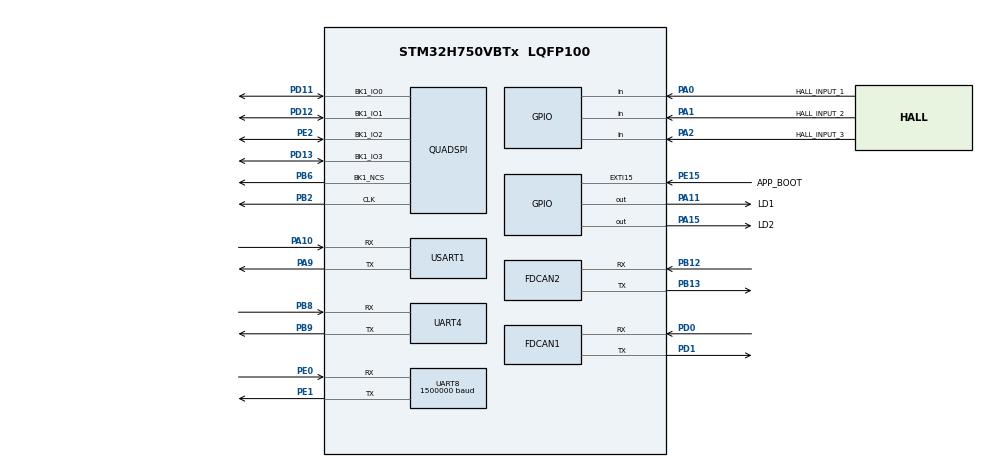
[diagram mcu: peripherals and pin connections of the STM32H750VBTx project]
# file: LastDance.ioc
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CORTEX_M7.CPU_ICache=Enabled
CORTEX_M7.default_mode_Activation=0
Dma.Request0=UART4_RX
Dma.Request1=UART8_TX
Dma.Request2=UART8_RX
Dma.Request3=USART1_TX
Dma.UART4_RX.0.Direction=DMA_PERIPH_TO_MEMORY
Dma.UART4_RX.0.EventEnable=DISABLE
Dma.UART4_RX.0.FIFOMode=DMA_FIFOMODE_DISABLE
Dma.UART4_RX.0.Instance=DMA1_Stream0
Dma.UART4_RX.0.MemDataAlignment=DMA_MDATAALIGN_BYTE
Dma.UART4_RX.0.MemInc=DMA_MINC_ENABLE
Dma.UART4_RX.0.Mode=DMA_NORMAL
Dma.UART4_RX.0.PeriphDataAlignment=DMA_PDATAALIGN_BYTE
Dma.UART4_RX.0.PeriphInc=DMA_PINC_DISABLE
Dma.UART4_RX.0.Polarity=HAL_DMAMUX_REQ_GEN_RISING
Dma.UART4_RX.0.Priority=DMA_PRIORITY_LOW
Dma.UART4_RX.0.RequestNumber=1
Dma.UART4_RX.0.SignalID=NONE
Dma.UART4_RX.0.SyncEnable=DISABLE
Dma.UART4_RX.0.SyncPolarity=HAL_DMAMUX_SYNC_NO_EVENT
Dma.UART4_RX.0.SyncRequestNumber=1
Dma.UART4_RX.0.SyncSignalID=NONE
Dma.UART8_RX.2.Direction=DMA_PERIPH_TO_MEMORY
Dma.UART8_RX.2.EventEnable=DISABLE
Dma.UART8_RX.2.FIFOMode=DMA_FIFOMODE_DISABLE
Dma.UART8_RX.2.Instance=DMA1_Stream2
Dma.UART8_RX.2.MemDataAlignment=DMA_MDATAALIGN_BYTE
Dma.UART8_RX.2.MemInc=DMA_MINC_ENABLE
Dma.UART8_RX.2.Mode=DMA_NORMAL
Dma.UART8_RX.2.PeriphDataAlignment=DMA_PDATAALIGN_BYTE
Dma.UART8_RX.2.PeriphInc=DMA_PINC_DISABLE
Dma.UART8_RX.2.Polarity=HAL_DMAMUX_REQ_GEN_RISING
Dma.UART8_RX.2.Priority=DMA_PRIORITY_LOW
Dma.UART8_RX.2.RequestNumber=1
Dma.UART8_RX.2.SignalID=NONE
Dma.UART8_RX.2.SyncEnable=DISABLE
Dma.UART8_RX.2.SyncPolarity=HAL_DMAMUX_SYNC_NO_EVENT
Dma.UART8_RX.2.SyncRequestNumber=1
Dma.UART8_RX.2.SyncSignalID=NONE
Dma.UART8_TX.1.Direction=DMA_MEMORY_TO_PERIPH
Dma.UART8_TX.1.EventEnable=DISABLE
Dma.UART8_TX.1.FIFOMode=DMA_FIFOMODE_DISABLE
Dma.UART8_TX.1.Instance=DMA1_Stream1
Dma.UART8_TX.1.MemDataAlignment=DMA_MDATAALIGN_BYTE
Dma.UART8_TX.1.MemInc=DMA_MINC_ENABLE
Dma.UART8_TX.1.Mode=DMA_NORMAL
Dma.UART8_TX.1.PeriphDataAlignment=DMA_PDATAALIGN_BYTE
Dma.UART8_TX.1.PeriphInc=DMA_PINC_DISABLE
Dma.UART8_TX.1.Polarity=HAL_DMAMUX_REQ_GEN_RISING
Dma.UART8_TX.1.Priority=DMA_PRIORITY_LOW
Dma.UART8_TX.1.RequestNumber=1
Dma.UART8_TX.1.SignalID=NONE
Dma.UART8_TX.1.SyncEnable=DISABLE
Dma.UART8_TX.1.SyncPolarity=HAL_DMAMUX_SYNC_NO_EVENT
Dma.UART8_TX.1.SyncRequestNumber=1
Dma.UART8_TX.1.SyncSignalID=NONE
Dma.USART1_TX.3.Direction=DMA_MEMORY_TO_PERIPH
Dma.USART1_TX.3.EventEnable=DISABLE
Dma.USART1_TX.3.FIFOMode=DMA_FIFOMODE_DISABLE
Dma.USART1_TX.3.Instance=DMA1_Stream3
Dma.USART1_TX.3.MemDataAlignment=DMA_MDATAALIGN_BYTE
Dma.USART1_TX.3.MemInc=DMA_MINC_ENABLE
Dma.USART1_TX.3.Mode=DMA_NORMAL
Dma.USART1_TX.3.PeriphDataAlignment=DMA_PDATAALIGN_BYTE
Dma.USART1_TX.3.PeriphInc=DMA_PINC_DISABLE
Dma.USART1_TX.3.Polarity=HAL_DMAMUX_REQ_GEN_RISING
Dma.USART1_TX.3.Priority=DMA_PRIORITY_LOW
Dma.USART1_TX.3.RequestNumber=1
Dma.USART1_TX.3.SignalID=NONE
Dma.USART1_TX.3.SyncEnable=DISABLE
Dma.USART1_TX.3.SyncPolarity=HAL_DMAMUX_SYNC_NO_EVENT
Dma.USART1_TX.3.SyncRequestNumber=1
Dma.USART1_TX.3.SyncSignalID=NONE
FDCAN1.AutoRetransmission=ENABLE
FDCAN1.CalculateBaudRateNominal=250000
FDCAN1.CalculateTimeBitNominal=4000
FDCAN1.CalculateTimeQuantumNominal=800.0
FDCAN1.DataSyncJumpWidth=3
FDCAN1.DataTimeSeg1=14
FDCAN1.DataTimeSeg2=5
FDCAN1.NominalSyncJumpWidth=3
FDCAN1.RxFifo0ElmtsNbr=12
FDCAN1.StdFiltersNbr=1
FDCAN1.TxFifoQueueElmtsNbr=32
FDCAN2.AutoRetransmission=ENABLE
FDCAN2.CalculateBaudRateNominal=250000
FDCAN2.CalculateTimeBitNominal=4000
FDCAN2.CalculateTimeQuantumNominal=800.0
FDCAN2.DataSyncJumpWidth=3
FDCAN2.DataTimeSeg1=14
FDCAN2.DataTimeSeg2=5
FDCAN2.MessageRAMOffset=1280
FDCAN2.NominalSyncJumpWidth=3
FDCAN2.RxFifo0ElmtsNbr=12
FDCAN2.StdFiltersNbr=1
FDCAN2.TxFifoQueueElmtsNbr=32
FREERTOS.INCLUDE_eTaskGetState=1
FREERTOS.INCLUDE_pcTaskGetTaskName=1
FREERTOS.INCLUDE_uxTaskGetStackHighWaterMark=1
FREERTOS.INCLUDE_uxTaskGetStackHighWaterMark2=1
FREERTOS.INCLUDE_vTaskCleanUpResources=1
FREERTOS.INCLUDE_vTaskDelayUntil=1
FREERTOS.INCLUDE_xQueueGetMutexHolder=0
FREERTOS.INCLUDE_xSemaphoreGetMutexHolder=1
FREERTOS.INCLUDE_xTaskAbortDelay=1
FREERTOS.INCLUDE_xTaskGetCurrentTaskHandle=1
FREERTOS.INCLUDE_xTaskGetHandle=1
FREERTOS.Queues01=qMotorTimeup,1,uint8_t,0,Static,qMotorTimeupBuffer,qMotorTimeupControlBlock;qSerialPack,8,uint32_t,0,Static,qSerialPackBuffer,qSerialPackControlBlock
FREERTOS.Tasks01=initMotorDirect,0,512,initMotorDirectionTaskFunc,As weak,NULL,Static,initMotorDirectBuffer,initMotorDirectControlBlock;MotorRoutineTask,3,512,motorRoutineTaskFunc,As external,NULL,Static,MotorRoutineTaskBuffer,MotorRoutineTaskControlBlock;SerialCmdProcTask,-3,512,serialCmdProcTaskFunc,As external,NULL,Static,SerialCmdProcTaskBuffer,SerialCmdProcTaskControlBlock
FREERTOS.configCHECK_FOR_STACK_OVERFLOW=2
FREERTOS.configENABLE_FPU=1
FREERTOS.configGENERATE_RUN_TIME_STATS=1
FREERTOS.configMAX_TASK_NAME_LEN=20
FREERTOS.configRECORD_STACK_HIGH_ADDRESS=1
FREERTOS.configTOTAL_HEAP_SIZE=8192
FREERTOS.configUSE_APPLICATION_TASK_TAG=1
FREERTOS.configUSE_COUNTING_SEMAPHORES=1
FREERTOS.configUSE_MALLOC_FAILED_HOOK=1
FREERTOS.configUSE_NEWLIB_REENTRANT=1
FREERTOS.configUSE_STATS_FORMATTING_FUNCTIONS=1
FREERTOS.configUSE_TRACE_FACILITY=1
Mcu.Family=STM32H7
Mcu.Name=STM32H750VBTx
Mcu.Package=LQFP100
NVIC.DMA1_Stream0_IRQn=true\:5\:0\:false\:false\:true\:true\:false\:true\:true
NVIC.DMA1_Stream1_IRQn=true\:5\:0\:false\:false\:true\:true\:false\:true\:true
NVIC.DMA1_Stream2_IRQn=true\:5\:0\:false\:false\:true\:true\:false\:true\:true
NVIC.DMA1_Stream3_IRQn=true\:5\:0\:false\:false\:true\:true\:false\:true\:true
NVIC.EXTI15_10_IRQn=true\:5\:0\:false\:false\:true\:false\:true\:true\:true
NVIC.FDCAN1_IT0_IRQn=true\:5\:0\:false\:false\:true\:true\:true\:true\:true
NVIC.FDCAN1_IT1_IRQn=true\:5\:0\:false\:false\:true\:true\:true\:true\:true
NVIC.FDCAN2_IT0_IRQn=true\:5\:0\:false\:false\:true\:true\:true\:true\:true
NVIC.FDCAN2_IT1_IRQn=true\:5\:0\:false\:false\:true\:true\:true\:true\:true
NVIC.FDCAN_CAL_IRQn=true\:5\:0\:false\:false\:true\:true\:true\:true\:true
NVIC.PriorityGroup=NVIC_PRIORITYGROUP_4
NVIC.TIM6_DAC_IRQn=true\:5\:0\:false\:false\:true\:true\:true\:true\:true
NVIC.TIM7_IRQn=true\:15\:0\:false\:false\:true\:false\:false\:true\:true
NVIC.TimeBase=TIM7_IRQn
NVIC.TimeBaseIP=TIM7
NVIC.UART8_IRQn=true\:5\:0\:false\:false\:true\:true\:true\:true\:true
PA0.GPIO_Label=HALL_INPUT_1
PA0.Signal=GPIO_Input
PA1.GPIO_Label=HALL_INPUT_2
PA1.Signal=GPIO_Input
PA10.Mode=Asynchronous
PA10.Signal=USART1_RX
PA11.GPIO_Label=LD1
PA11.Signal=GPIO_Output
PA13\ (JTMS/SWDIO).Mode=Serial_Wire
PA13\ (JTMS/SWDIO).Signal=DEBUG_JTMS-SWDIO
PA14\ (JTCK/SWCLK).Mode=Serial_Wire
PA14\ (JTCK/SWCLK).Signal=DEBUG_JTCK-SWCLK
PA15\ (JTDI).GPIO_Label=LD2
PA15\ (JTDI).Signal=GPIO_Output
PA2.GPIO_Label=HALL_INPUT_3
PA2.Signal=GPIO_Input
PA9.Mode=Asynchronous
PA9.Signal=USART1_TX
PB12.GPIO_Mode=GPIO_MODE_AF_PP
PB12.GPIO_PuPd=GPIO_NOPULL
PB12.GPIO_Speed=GPIO_SPEED_FREQ_VERY_HIGH
PB12.Mode=FDCAN_Activate
PB12.Signal=FDCAN2_RX
PB13.GPIO_Mode=GPIO_MODE_AF_PP
PB13.GPIO_PuPd=GPIO_NOPULL
PB13.GPIO_Speed=GPIO_SPEED_FREQ_VERY_HIGH
PB13.Mode=FDCAN_Activate
PB13.Signal=FDCAN2_TX
PB2.GPIO_Mode=GPIO_MODE_AF_PP
PB2.GPIO_PuPd=GPIO_NOPULL
PB2.GPIO_Speed=GPIO_SPEED_FREQ_VERY_HIGH
PB2.Mode=Single Bank 1
PB2.Signal=QUADSPI_CLK
PB6.GPIO_Mode=GPIO_MODE_AF_PP
PB6.GPIO_PuPd=GPIO_NOPULL
PB6.GPIO_Speed=GPIO_SPEED_FREQ_VERY_HIGH
PB6.Mode=Single Bank 1
PB6.Signal=QUADSPI_BK1_NCS
PB8.GPIO_ModeDefaultPP=GPIO_MODE_AF_PP
PB8.GPIO_PuPd=GPIO_NOPULL
PB8.GPIO_Speed=GPIO_SPEED_FREQ_VERY_HIGH
PB8.Mode=Asynchronous
PB8.Signal=UART4_RX
PB9.GPIO_ModeDefaultPP=GPIO_MODE_AF_PP
PB9.GPIO_PuPd=GPIO_NOPULL
PB9.GPIO_Speed=GPIO_SPEED_FREQ_VERY_HIGH
PB9.Mode=Asynchronous
PB9.Signal=UART4_TX
PD0.GPIO_Mode=GPIO_MODE_AF_PP
PD0.GPIO_PuPd=GPIO_NOPULL
PD0.GPIO_Speed=GPIO_SPEED_FREQ_VERY_HIGH
PD0.Mode=FDCAN_Activate
PD0.Signal=FDCAN1_RX
PD1.GPIO_Mode=GPIO_MODE_AF_PP
PD1.GPIO_PuPd=GPIO_NOPULL
PD1.GPIO_Speed=GPIO_SPEED_FREQ_VERY_HIGH
PD1.Mode=FDCAN_Activate
PD1.Signal=FDCAN1_TX
PD11.GPIO_Mode=GPIO_MODE_AF_PP
PD11.GPIO_PuPd=GPIO_NOPULL
PD11.GPIO_Speed=GPIO_SPEED_FREQ_VERY_HIGH
PD11.Mode=Single Bank 1
PD11.Signal=QUADSPI_BK1_IO0
PD12.GPIO_Mode=GPIO_MODE_AF_PP
PD12.GPIO_PuPd=GPIO_NOPULL
PD12.GPIO_Speed=GPIO_SPEED_FREQ_VERY_HIGH
PD12.Mode=Single Bank 1
PD12.Signal=QUADSPI_BK1_IO1
PD13.GPIO_Mode=GPIO_MODE_AF_PP
PD13.GPIO_PuPd=GPIO_NOPULL
PD13.GPIO_Speed=GPIO_SPEED_FREQ_VERY_HIGH
PD13.Mode=Single Bank 1
PD13.Signal=QUADSPI_BK1_IO3
PE0.GPIO_ModeDefaultPP=GPIO_MODE_AF_PP
PE0.GPIO_PuPd=GPIO_NOPULL
PE0.GPIO_Speed=GPIO_SPEED_FREQ_VERY_HIGH
PE0.Mode=Asynchronous
PE0.Signal=UART8_RX
PE1.GPIO_ModeDefaultPP=GPIO_MODE_AF_PP
PE1.GPIO_PuPd=GPIO_NOPULL
PE1.GPIO_Speed=GPIO_SPEED_FREQ_VERY_HIGH
PE1.Mode=Asynchronous
PE1.Signal=UART8_TX
PE15.GPIO_Label=APP_BOOT
PE15.Signal=GPXTI15
PE2.GPIO_Mode=GPIO_MODE_AF_PP
PE2.GPIO_PuPd=GPIO_NOPULL
PE2.GPIO_Speed=GPIO_SPEED_FREQ_VERY_HIGH
PE2.Mode=Single Bank 1
PE2.Signal=QUADSPI_BK1_IO2
PH0-OSC_IN\ (PH0).Mode=HSE-External-Oscillator
PH0-OSC_IN\ (PH0).Signal=RCC_OSC_IN
PH1-OSC_OUT\ (PH1).Mode=HSE-External-Oscillator
PH1-OSC_OUT\ (PH1).Signal=RCC_OSC_OUT
ProjectManager.HeapSize=0x800
ProjectManager.StackSize=0x800
ProjectManager.TargetToolchain=Makefile
QUADSPI.ChipSelectHighTime=QSPI_CS_HIGH_TIME_6_CYCLE
QUADSPI.ClockPrescaler=2-1
QUADSPI.FifoThreshold=4
QUADSPI.FlashSize=23-1
QUADSPI.SampleShifting=QSPI_SAMPLE_SHIFTING_HALFCYCLE
RCC.ADCFreq_Value=120000000
RCC.APB1Freq_Value=60000000
RCC.APB2Freq_Value=60000000
RCC.APB3Freq_Value=60000000
RCC.APB4Freq_Value=60000000
RCC.CortexFreq_Value=60000000
RCC.Cortex_Div=SYSTICK_CLKSOURCE_HCLK_DIV8
RCC.D1PPRE=RCC_APB3_DIV4
RCC.D2PPRE1=RCC_APB1_DIV4
RCC.D2PPRE2=RCC_APB2_DIV4
RCC.D3PPRE=RCC_APB4_DIV4
RCC.DIVM1=5
RCC.DIVM2=5
RCC.DIVN1=192
RCC.DIVN2=48
RCC.DIVQ1=48
RCC.DIVR2=1
RCC.HCLKFreq_Value=240000000
RCC.HPRE=RCC_HCLK_DIV2
RCC.PLLSourceVirtual=RCC_PLLSOURCE_HSE
RCC.SYSCLKFreq_VALUE=480000000
RCC.SYSCLKSource=RCC_SYSCLKSOURCE_PLLCLK
RCC.USBFreq_Value=20000000
TIM6.Period=3000-1
TIM6.Prescaler=120-1
UART4.DMADisableonRxErrorParam=UART_ADVFEATURE_DMA_DISABLEONRXERROR
UART4.OverrunDisableParam=UART_ADVFEATURE_OVERRUN_DISABLE
UART8.BaudRate=1500000
UART8.DMADisableonRxErrorParam=UART_ADVFEATURE_DMA_DISABLEONRXERROR
UART8.OverrunDisableParam=UART_ADVFEATURE_OVERRUN_DISABLE
USART1.DMADisableonRxErrorParam=ADVFEATURE_DMA_DISABLEONRXERROR
USART1.OverrunDisableParam=ADVFEATURE_OVERRUN_DISABLE
USART1.VirtualMode-Asynchronous=VM_ASYNC
VP_FREERTOS_VS_CMSIS_V1.Mode=CMSIS_V1
VP_SYS_VS_tim7.Mode=TIM7
VP_TIM6_VS_ClockSourceINT.Mode=Enable_Timer
board=custom

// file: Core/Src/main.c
/* USER CODE BEGIN Header */
/**
  ******************************************************************************
  * @file           : main.c
  * @brief          : Main program body
  ******************************************************************************
  * @attention
  *
  * Copyright (c) 2022 STMicroelectronics.
  * All rights reserved.
  *
  * This software is licensed under terms that can be found in the LICENSE file
  * in the root directory of this software component.
  * If no LICENSE file comes with this software, it is provided AS-IS.
  *
  ******************************************************************************
  */
/* USER CODE END Header */
#include "main.h"
#include "cmsis_os.h"
#include "dma.h"
#include "fdcan.h"
#include "tim.h"
#include "usart.h"
#include "gpio.h"

void SystemClock_Config(void);
void MX_FREERTOS_Init(void);

/* USER CODE BEGIN 0 */
extern void fdcanfilter(void);
/* USER CODE END 0 */

int main(void)
{

  /* Enable I-Cache---------------------------------------------------------*/
  SCB_EnableICache();

  /* MCU Configuration--------------------------------------------------------*/

  /* Reset of all peripherals, Initializes the Flash interface and the Systick. */
  HAL_Init();

  /* Configure the system clock */
  SystemClock_Config();

  /* Initialize all configured peripherals */
  MX_GPIO_Init();
  MX_DMA_Init();
  MX_FDCAN2_Init();
  MX_UART4_Init();
  MX_UART8_Init();
  MX_FDCAN1_Init();
  MX_TIM6_Init();
  MX_USART1_UART_Init();
  /* USER CODE BEGIN 2 */
  fdcanfilter();

  ST_LOGI("Welcome");

  /* USER CODE END 2 */

  /* Call init function for freertos objects (in freertos.c) */
  MX_FREERTOS_Init();

  /* Start scheduler */
  osKernelStart();

  /* We should never get here as control is now taken by the scheduler */
  /* Infinite loop */
  while (1)
  {

  }
}

void SystemClock_Config(void)
{
  RCC_OscInitTypeDef RCC_OscInitStruct = {0};
  RCC_ClkInitTypeDef RCC_ClkInitStruct = {0};

  /** Supply configuration update enable
  */
  HAL_PWREx_ConfigSupply(PWR_LDO_SUPPLY);

  /** Configure the main internal regulator output voltage
  */
  __HAL_PWR_VOLTAGESCALING_CONFIG(PWR_REGULATOR_VOLTAGE_SCALE1);

  while(!__HAL_PWR_GET_FLAG(PWR_FLAG_VOSRDY)) {}

  __HAL_RCC_SYSCFG_CLK_ENABLE();
  __HAL_PWR_VOLTAGESCALING_CONFIG(PWR_REGULATOR_VOLTAGE_SCALE0);

  while(!__HAL_PWR_GET_FLAG(PWR_FLAG_VOSRDY)) {}

  /** Initializes the RCC Oscillators according to the specified parameters
  * in the RCC_OscInitTypeDef structure.
  */
  RCC_OscInitStruct.OscillatorType = RCC_OSCILLATORTYPE_HSE;
  RCC_OscInitStruct.HSEState = RCC_HSE_ON;
  RCC_OscInitStruct.PLL.PLLState = RCC_PLL_ON;
  RCC_OscInitStruct.PLL.PLLSource = RCC_PLLSOURCE_HSE;
  RCC_OscInitStruct.PLL.PLLM = 5;
  RCC_OscInitStruct.PLL.PLLN = 192;
  RCC_OscInitStruct.PLL.PLLP = 2;
  RCC_OscInitStruct.PLL.PLLQ = 48;
  RCC_OscInitStruct.PLL.PLLR = 2;
  RCC_OscInitStruct.PLL.PLLRGE = RCC_PLL1VCIRANGE_2;
  RCC_OscInitStruct.PLL.PLLVCOSEL = RCC_PLL1VCOWIDE;
  RCC_OscInitStruct.PLL.PLLFRACN = 0;
  if (HAL_RCC_OscConfig(&RCC_OscInitStruct) != HAL_OK)
  {
    Error_Handler();
  }

  /** Initializes the CPU, AHB and APB buses clocks
  */
  RCC_ClkInitStruct.ClockType = RCC_CLOCKTYPE_HCLK|RCC_CLOCKTYPE_SYSCLK
                              |RCC_CLOCKTYPE_PCLK1|RCC_CLOCKTYPE_PCLK2
                              |RCC_CLOCKTYPE_D3PCLK1|RCC_CLOCKTYPE_D1PCLK1;
  RCC_ClkInitStruct.SYSCLKSource = RCC_SYSCLKSOURCE_PLLCLK;
  RCC_ClkInitStruct.SYSCLKDivider = RCC_SYSCLK_DIV1;
  RCC_ClkInitStruct.AHBCLKDivider = RCC_HCLK_DIV2;
  RCC_ClkInitStruct.APB3CLKDivider = RCC_APB3_DIV4;
  RCC_ClkInitStruct.APB1CLKDivider = RCC_APB1_DIV4;
  RCC_ClkInitStruct.APB2CLKDivider = RCC_APB2_DIV4;
  RCC_ClkInitStruct.APB4CLKDivider = RCC_APB4_DIV4;

  if (HAL_RCC_ClockConfig(&RCC_ClkInitStruct, FLASH_LATENCY_4) != HAL_OK)
  {
    Error_Handler();
  }
}

/* USER CODE BEGIN 4 */
extern void JumpToBootLoader(void);
/* USER CODE END 4 */

void HAL_TIM_PeriodElapsedCallback(TIM_HandleTypeDef *htim)
{
  if (htim->Instance == TIM7) {
    HAL_IncTick();
  }
  /* USER CODE BEGIN Callback 1 */
  // else if (htim->Instance == TIM6){
  // }
  /* USER CODE END Callback 1 */
}

void Error_Handler(void)
{
  /* USER CODE BEGIN Error_Handler_Debug */
  /* User can add his own implementation to report the HAL error return state */
  ST_LOGE("error handler");
  JumpToBootLoader();
  __disable_irq();
  while (1)
  {
    ST_LOGE("Jump Fail");
    // if (HAL_GPIO_ReadPin(APP_BOOT_GPIO_Port, APP_BOOT_Pin) == GPIO_PIN_SET){
    //   JumpToBootLoader();
    // }
  }
  /* USER CODE END Error_Handler_Debug */
}

#ifdef  USE_FULL_ASSERT
/**
  * @brief  Reports the name of the source file and the source line number
  *         where the assert_param error has occurred.
  * @param  file: pointer to the source file name
  * @param  line: assert_param error line source number
  * @retval None
  */
void assert_failed(uint8_t *file, uint32_t line)
{
  /* USER CODE BEGIN 6 */
  uart_printf("["LOG_COLOR_E"%s:%lu"LOG_RESET_COLOR"] assert "LOG_COLOR_E"Fail"LOG_RESET_COLOR"\n", file, line);
  /* USER CODE END 6 */
}
#endif /* USE_FULL_ASSERT */

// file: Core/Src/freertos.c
/* USER CODE BEGIN Header */
/**
  ******************************************************************************
  * File Name          : freertos.c
  * Description        : Code for freertos applications
  ******************************************************************************
  * @attention
  *
  * Copyright (c) 2022 STMicroelectronics.
  * All rights reserved.
  *
  * This software is licensed under terms that can be found in the LICENSE file
  * in the root directory of this software component.
  * If no LICENSE file comes with this software, it is provided AS-IS.
  *
  ******************************************************************************
  */
/* USER CODE END Header */

#include "FreeRTOS.h"
#include "task.h"
#include "main.h"
#include "cmsis_os.h"

/* USER CODE BEGIN Includes */
#include "CarTasks/CarTasks.h"
/* USER CODE END Includes */

osThreadId initMotorDirectHandle;
uint32_t initMotorDirectBuffer[ 512 ];
osStaticThreadDef_t initMotorDirectControlBlock;
osThreadId MotorRoutineTaskHandle;
uint32_t MotorRoutineTaskBuffer[ 512 ];
osStaticThreadDef_t MotorRoutineTaskControlBlock;
osThreadId SerialCmdProcTaskHandle;
uint32_t SerialCmdProcTaskBuffer[ 512 ];
osStaticThreadDef_t SerialCmdProcTaskControlBlock;
osMessageQId qMotorTimeupHandle;
uint8_t qMotorTimeupBuffer[ 1 * sizeof( uint8_t ) ];
osStaticMessageQDef_t qMotorTimeupControlBlock;
osMessageQId qSerialPackHandle;
uint8_t qSerialPackBuffer[ 8 * sizeof( uint32_t ) ];
osStaticMessageQDef_t qSerialPackControlBlock;

void initMotorDirectionTaskFunc(void const * argument);
extern void motorRoutineTaskFunc(void const * argument);
extern void serialCmdProcTaskFunc(void const * argument);

void MX_FREERTOS_Init(void); /* (MISRA C 2004 rule 8.1) */

/* GetIdleTaskMemory prototype (linked to static allocation support) */
void vApplicationGetIdleTaskMemory( StaticTask_t **ppxIdleTaskTCBBuffer, StackType_t **ppxIdleTaskStackBuffer, uint32_t *pulIdleTaskStackSize );

/* Hook prototypes */
void configureTimerForRunTimeStats(void);
unsigned long getRunTimeCounterValue(void);
void vApplicationStackOverflowHook(xTaskHandle xTask, signed char *pcTaskName);
void vApplicationMallocFailedHook(void);

/* USER CODE BEGIN 1 */
/* Functions needed when configGENERATE_RUN_TIME_STATS is on */
__weak void configureTimerForRunTimeStats(void)
{

}

__weak unsigned long getRunTimeCounterValue(void)
{
return 0;
}
/* USER CODE END 1 */

/* USER CODE BEGIN 4 */
__weak void vApplicationStackOverflowHook(xTaskHandle xTask, signed char *pcTaskName)
{
  ST_LOGE("task overflow detected: %s",pcTaskName);
}
/* USER CODE END 4 */

/* USER CODE BEGIN 5 */
__weak void vApplicationMallocFailedHook(void)
{
   ST_LOGE("malloc fail detected");
}
/* USER CODE END 5 */

/* USER CODE BEGIN GET_IDLE_TASK_MEMORY */
static StaticTask_t xIdleTaskTCBBuffer;
static StackType_t xIdleStack[configMINIMAL_STACK_SIZE];

void vApplicationGetIdleTaskMemory( StaticTask_t **ppxIdleTaskTCBBuffer, StackType_t **ppxIdleTaskStackBuffer, uint32_t *pulIdleTaskStackSize )
{
  *ppxIdleTaskTCBBuffer = &xIdleTaskTCBBuffer;
  *ppxIdleTaskStackBuffer = &xIdleStack[0];
  *pulIdleTaskStackSize = configMINIMAL_STACK_SIZE;
  /* place for user code */
}
/* USER CODE END GET_IDLE_TASK_MEMORY */

void MX_FREERTOS_Init(void) {

  /* Create the queue(s) */
  /* definition and creation of qMotorTimeup */
  osMessageQStaticDef(qMotorTimeup, 1, uint8_t, qMotorTimeupBuffer, &qMotorTimeupControlBlock);
  qMotorTimeupHandle = osMessageCreate(osMessageQ(qMotorTimeup), NULL);

  /* definition and creation of qSerialPack */
  osMessageQStaticDef(qSerialPack, 8, uint32_t, qSerialPackBuffer, &qSerialPackControlBlock);
  qSerialPackHandle = osMessageCreate(osMessageQ(qSerialPack), NULL);

  /* Create the thread(s) */
  /* definition and creation of initMotorDirect */
  osThreadStaticDef(initMotorDirect, initMotorDirectionTaskFunc, osPriorityNormal, 0, 512, initMotorDirectBuffer, &initMotorDirectControlBlock);
  initMotorDirectHandle = osThreadCreate(osThread(initMotorDirect), NULL);

  /* definition and creation of MotorRoutineTask */
  osThreadStaticDef(MotorRoutineTask, motorRoutineTaskFunc, osPriorityRealtime, 0, 512, MotorRoutineTaskBuffer, &MotorRoutineTaskControlBlock);
  MotorRoutineTaskHandle = osThreadCreate(osThread(MotorRoutineTask), NULL);

  /* definition and creation of SerialCmdProcTask */
  osThreadStaticDef(SerialCmdProcTask, serialCmdProcTaskFunc, osPriorityIdle, 0, 512, SerialCmdProcTaskBuffer, &SerialCmdProcTaskControlBlock);
  SerialCmdProcTaskHandle = osThreadCreate(osThread(SerialCmdProcTask), NULL);

}

__weak void initMotorDirectionTaskFunc(void const * argument)
{
  for(;;)
  {
    osDelay(1);
  }
}
